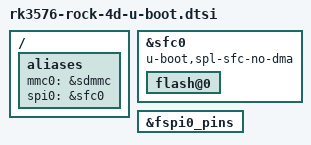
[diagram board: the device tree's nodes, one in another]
// SPDX-License-Identifier: (GPL-2.0+ OR MIT)

#include "rk3576-u-boot.dtsi"

/ {
	aliases {
		mmc0 = &sdmmc;
		spi0 = &sfc0;
	};
};

&sfc0 {
	u-boot,spl-sfc-no-dma;
	bootph-pre-ram;
	bootph-some-ram;

	flash@0 {
		bootph-pre-ram;
		bootph-some-ram;
	};
};

&fspi0_pins {
	bootph-pre-ram;
	bootph-some-ram;
};
